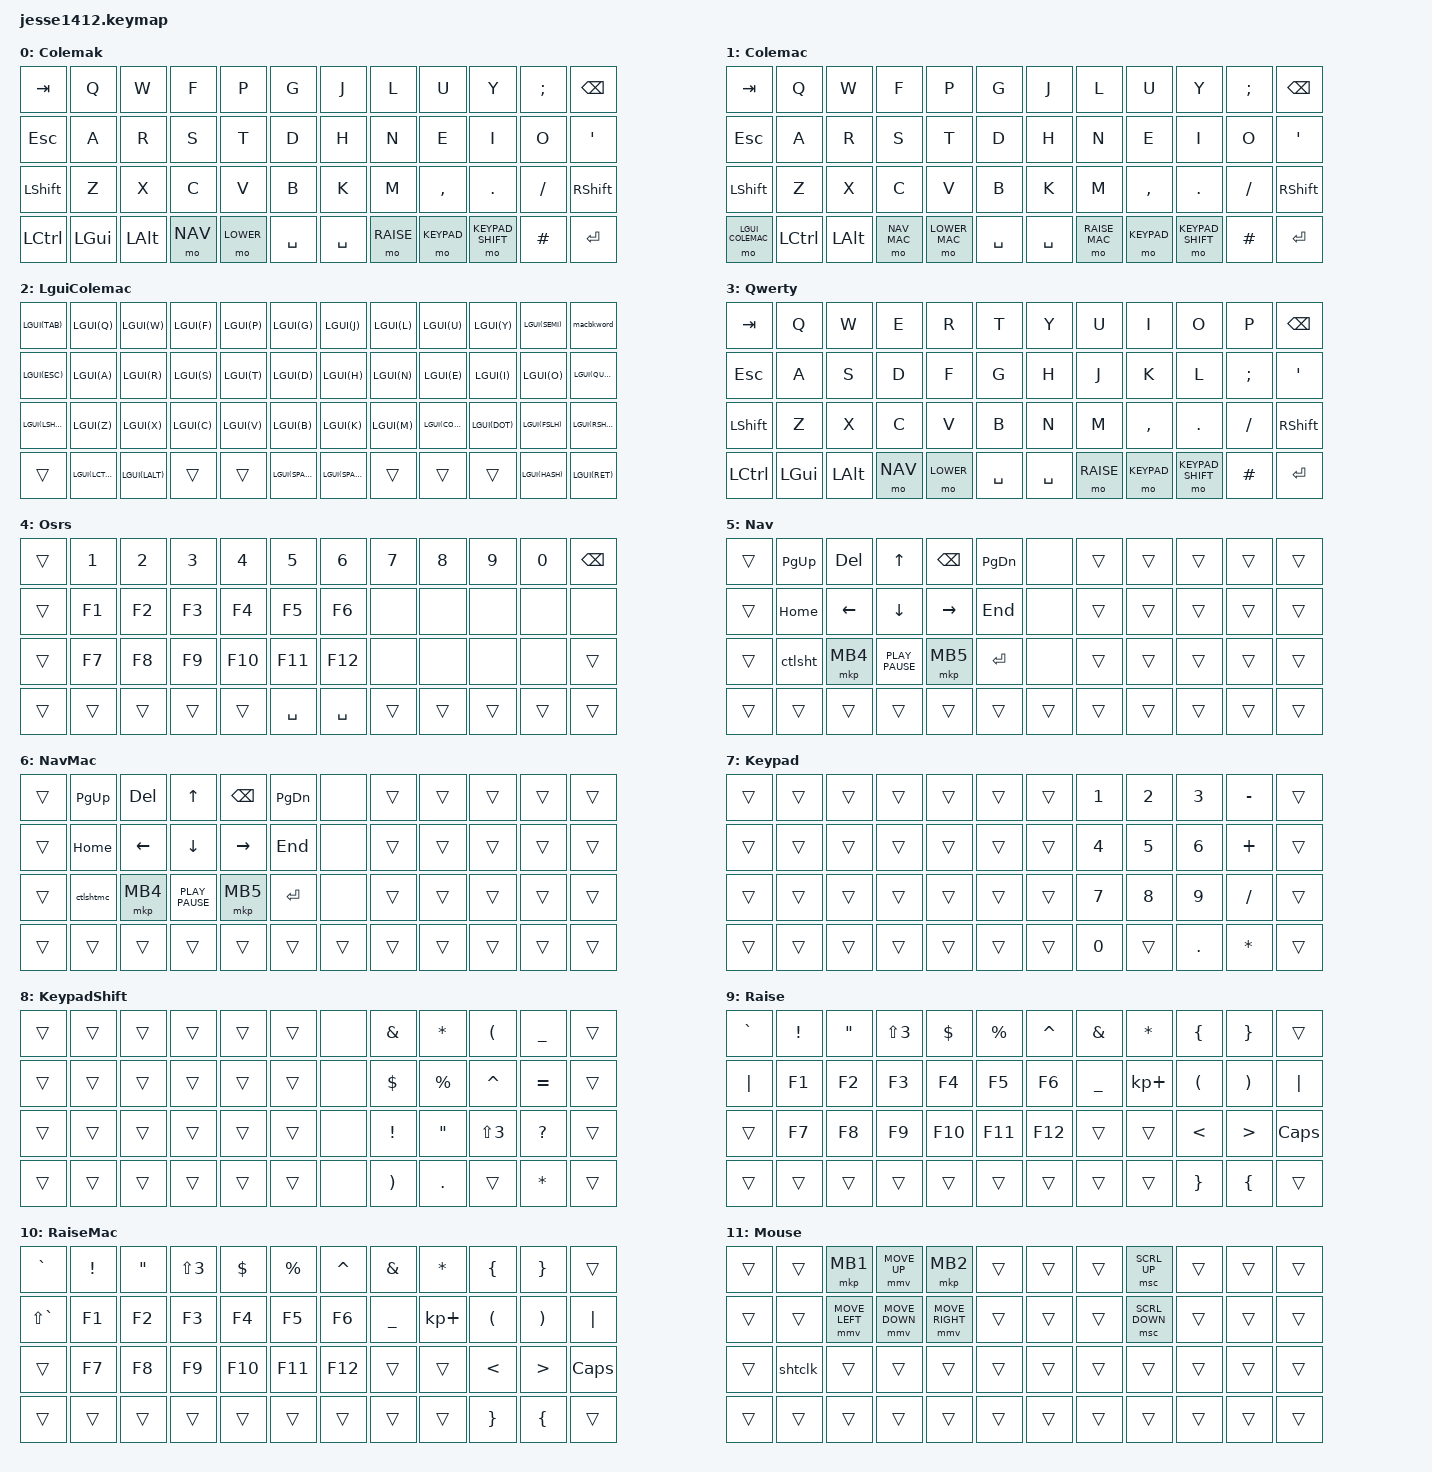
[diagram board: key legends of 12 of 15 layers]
/*
 * Copyright (c) 2022 Pete Johanson
 *
 * SPDX-License-Identifier: MIT
 */

#define ZMK_POINTING_DEFAULT_MOVE_VAL 600  // default: 600
#define ZMK_POINTING_DEFAULT_SCRL_VAL 10    // default: 10

#include <behaviors.dtsi>
#include <dt-bindings/zmk/keys.h>
#include <dt-bindings/zmk/bt.h>
#include <dt-bindings/zmk/outputs.h>
#include <dt-bindings/zmk/pointing.h>


// Layers
#define COLEMAK 0
#define COLEMAC 1
#define LGUI_COLEMAC 2
#define QWERTY 3
#define OSRS 4
#define NAV 5
#define NAV_MAC 6
#define KEYPAD 7
#define KEYPAD_SHIFT 8
#define RAISE 9
#define RAISE_MAC 10
#define MOUSE 11
#define LOWER 12
#define LOWER_MAC 13
#define ADJUST 14

// Using layer taps on thumbs, having quick tap as well helps w/ repeating space/backspace
&lt { quick_tap_ms = <200>; };

/ {
    chosen {
       zmk,physical-layout = &layout_ortho_4x12_all1u;
    };

    macros {
        ctlsht: ctlsht {
            compatible = "zmk,behavior-macro";
            #binding-cells = <0>;
            bindings
                = <&macro_press &kp LSHFT>
                , <&macro_press &kp LCTRL>
                , <&macro_pause_for_release>
                , <&macro_release &kp LCTRL>
                , <&macro_release &kp LSHFT>
                ;
        };
        ctlshtmc: ctlshtmc {
            compatible = "zmk,behavior-macro";
            #binding-cells = <0>;
            bindings
                = <&macro_press &kp LSHFT>
                , <&macro_press &kp LALT>
                , <&macro_pause_for_release>
                , <&macro_release &kp LALT>
                , <&macro_release &kp LSHFT>
                ;
        };
        // macpip: macpip {
        //     compatible = "zmk,behavior-macro";
        //     #binding-cells = <0>;
        //     bindings
        //         = <&macro_press &kp LSHFT>
        //         , <&macro_press  &kp GRAVE>
        //         , <&macro_pause_for_release>
        //         , <&macro_release &kp LSHFT>
        //         , <&macro_release &kp GRAVE>
        //         ;
        // };
        macbkword: macbkword {
            compatible = "zmk,behavior-macro";
            #binding-cells = <0>;
            bindings
                = <&macro_press &kp LALT>
                , <&macro_press &kp BSPC>
                , <&macro_pause_for_release>
                , <&macro_release &kp BSPC>
                , <&macro_release &kp LALT>
                ;
        };
        shtclk: shtclk {
            compatible = "zmk,behavior-macro";
            #binding-cells = <0>;
            bindings
                = <&macro_press &kp LSHFT>
                , <&macro_press &mkp LCLK>
                , <&macro_pause_for_release>
                , <&macro_release &mkp LCLK>
                , <&macro_release &kp LSHFT>
                ;
        };
    };
    
    // combos {
    //     compatible = "zmk,combos";
    //     combo_macbksp {
    //         timeout-ms = <50>;
    //         key-positions = <0 1>;
    //         bindings = <&kp ESC>;
    //     };
    // };

    // tap_dances {
    // 	shifty: shift_caps_word {
    //         compatible = "zmk,behavior-tap-dance";
    //         label = "TD_SHIFTY";
    //         #binding-cells = <0>;
    //         tapping-term-ms = <150>;
    //         bindings = <&kp LSHFT>, <&caps_word>;
	//     };
    // };

    conditional_layers {
        compatible = "zmk,conditional-layers";
        low_raise {
            if-layers = <LOWER RAISE>;
            then-layer = <ADJUST>;
        };
        mac_low_raise {
            if-layers = <LOWER_MAC RAISE_MAC>;
            then-layer = <ADJUST>;
        };
        nav_raise {
            if-layers = <NAV RAISE>;
            then-layer = <MOUSE>;
        };
        mac_nav_raise {
            if-layers = <NAV_MAC RAISE_MAC>;
            then-layer = <MOUSE>;
        };
    };

    keymap {
        compatible = "zmk,keymap";

        colemak_layer {
            label = "Colemak";
            bindings = <
 &kp TAB    &kp Q      &kp W      &kp F       &kp P          &kp G          &kp J            &kp L          &kp U       &kp Y            &kp SEMI      &kp BKSP
 &kp ESC    &kp A      &kp R      &kp S       &kp T          &kp D          &kp H            &kp N          &kp E       &kp I            &kp O         &kp QUOT
 &kp LSHFT  &kp Z      &kp X      &kp C       &kp V          &kp B          &kp K            &kp M          &kp COMMA   &kp DOT          &kp FSLH      &kp RSHFT
 &kp LCTRL  &kp LGUI   &kp LALT   &mo NAV     &mo LOWER      &kp SPACE      &kp SPACE        &mo RAISE      &mo KEYPAD  &mo KEYPAD_SHIFT &kp HASH      &kp RET
            >;
        };
        colemac_layer {
            label = "Colemac";
            bindings = <
 &kp TAB            &kp Q      &kp W      &kp F       &kp P          &kp G          &kp J            &kp L          &kp U       &kp Y            &kp SEMI      &kp BKSP
 &kp ESC            &kp A      &kp R      &kp S       &kp T          &kp D          &kp H            &kp N          &kp E       &kp I            &kp O         &kp QUOT
 &kp LSHFT          &kp Z      &kp X      &kp C       &kp V          &kp B          &kp K            &kp M          &kp COMMA   &kp DOT          &kp FSLH      &kp RSHFT
 &mo LGUI_COLEMAC   &kp LCTRL  &kp LALT   &mo NAV_MAC &mo LOWER_MAC  &kp SPACE      &kp SPACE        &mo RAISE_MAC  &mo KEYPAD  &mo KEYPAD_SHIFT &kp HASH      &kp RET
            >;
        };
        lgui_colemac_layer {
            label = "LguiColemac";
            bindings = <
 &kp LGUI(TAB)    &kp LGUI(Q)      &kp LGUI(W)      &kp LGUI(F)       &kp LGUI(P)          &kp LGUI(G)          &kp LGUI(J)            &kp LGUI(L)          &kp LGUI(U)       &kp LGUI(Y)            &kp LGUI(SEMI)      &macbkword
 &kp LGUI(ESC)    &kp LGUI(A)      &kp LGUI(R)      &kp LGUI(S)       &kp LGUI(T)          &kp LGUI(D)          &kp LGUI(H)            &kp LGUI(N)          &kp LGUI(E)       &kp LGUI(I)            &kp LGUI(O)         &kp LGUI(QUOT)
 &kp LGUI(LSHFT)  &kp LGUI(Z)      &kp LGUI(X)      &kp LGUI(C)       &kp LGUI(V)          &kp LGUI(B)          &kp LGUI(K)            &kp LGUI(M)          &kp LGUI(COMMA)   &kp LGUI(DOT)          &kp LGUI(FSLH)      &kp LGUI(RSHFT)
 &trans           &kp LGUI(LCTRL)  &kp LGUI(LALT)   &trans            &trans               &kp LGUI(SPACE)      &kp LGUI(SPACE)        &trans               &trans            &trans                 &kp LGUI(HASH)      &kp LGUI(RET)
            >;
        };
        qwerty_layer {
            label = "Qwerty";
            bindings = <
 &kp TAB    &kp Q      &kp W      &kp E       &kp R          &kp T          &kp Y            &kp U          &kp I       &kp O            &kp P         &kp BKSP
 &kp ESC    &kp A      &kp S      &kp D       &kp F          &kp G          &kp H            &kp J          &kp K       &kp L            &kp SEMI      &kp QUOT
 &kp LSHFT  &kp Z      &kp X      &kp C       &kp V          &kp B          &kp N            &kp M          &kp COMMA   &kp DOT          &kp FSLH      &kp RSHFT
 &kp LCTRL  &kp LGUI   &kp LALT   &mo NAV     &mo LOWER      &kp SPACE      &kp SPACE        &mo RAISE      &mo KEYPAD  &mo KEYPAD_SHIFT &kp HASH      &kp RET
            >;
        };
        osrs_layer {
            label = "Osrs";
            bindings = <
 &trans     &kp N1     &kp N2     &kp N3      &kp N4         &kp N5         &kp N6           &kp N7         &kp N8      &kp N9        &kp N0        &kp BKSP
 &trans     &kp F1     &kp F2     &kp F3      &kp F4         &kp F5         &kp F6           &none          &none       &none         &none         &none 
 &trans     &kp F7     &kp F8     &kp F9      &kp F10        &kp F11        &kp F12          &none          &none       &none         &none         &trans  
 &trans     &trans     &trans     &trans      &trans         &kp SPACE      &kp SPACE        &trans         &trans      &trans        &trans        &trans  
            >;
        };
        nav_layer {
            label = "Nav";
            bindings = <
 &trans     &kp PG_UP  &kp DEL    &kp UP           &kp BKSP       &kp PG_DN      &none            &trans         &trans      &trans        &trans        &trans
 &trans     &kp HOME   &kp LEFT   &kp DOWN         &kp RIGHT      &kp END        &none            &trans         &trans      &trans        &trans        &trans
 &trans     &ctlsht    &mkp MB4   &kp K_PLAY_PAUSE &mkp MB5       &kp RET        &none            &trans         &trans      &trans        &trans        &trans
 &trans     &trans     &trans     &trans           &trans         &trans         &trans           &trans         &trans      &trans        &trans        &trans
            >;
        };
        nav_mac_layer {
            label = "NavMac";
            bindings = <
 &trans     &kp PG_UP  &kp DEL    &kp UP           &kp BKSP       &kp PG_DN      &none            &trans         &trans      &trans        &trans        &trans
 &trans     &kp HOME   &kp LEFT   &kp DOWN         &kp RIGHT      &kp END        &none            &trans         &trans      &trans        &trans        &trans
 &trans     &ctlshtmc  &mkp MB4   &kp K_PLAY_PAUSE &mkp MB5       &kp RET        &none            &trans         &trans      &trans        &trans        &trans
 &trans     &trans     &trans     &trans           &trans         &trans         &trans           &trans         &trans      &trans        &trans        &trans
            >;
        };
        keypad_layer {
            label = "Keypad";
            bindings = <
 &trans     &trans     &trans     &trans      &trans         &trans         &trans           &kp N1         &kp N2      &kp N3        &kp MINUS       &trans
 &trans     &trans     &trans     &trans      &trans         &trans         &trans           &kp N4         &kp N5      &kp N6        &kp PLUS        &trans
 &trans     &trans     &trans     &trans      &trans         &trans         &trans           &kp N7         &kp N8      &kp N9        &kp FSLH        &trans
 &trans     &trans     &trans     &trans      &trans         &trans         &trans           &kp N0         &trans      &kp DOT       &kp STAR        &trans
            >;
        };
        keypad_shift_layer {
            label = "KeypadShift";
            bindings = <
 &trans     &trans     &trans     &trans      &trans         &trans         &none           &kp AMPS       &kp STAR    &kp LPAR      &kp UNDER       &trans
 &trans     &trans     &trans     &trans      &trans         &trans         &none           &kp DLLR       &kp PRCNT   &kp CARET     &kp EQUAL       &trans
 &trans     &trans     &trans     &trans      &trans         &trans         &none           &kp EXCL       &kp DQT     &kp LS(N3)    &kp QMARK       &trans
 &trans     &trans     &trans     &trans      &trans         &trans         &none           &kp RPAR       &kp DOT     &trans        &kp STAR        &trans
            >;
        };
        raise_layer {
            label = "Raise";
            bindings = <
 &kp GRAVE  &kp EXCL   &kp DQT    &kp LS(N3)  &kp DLLR       &kp PRCNT      &kp CARET       &kp AMPS       &kp STAR    &kp LBRC      &kp RBRC        &trans
 &kp PIPE   &kp F1     &kp F2     &kp F3      &kp F4         &kp F5         &kp F6          &kp UNDER      &kp KP_PLUS &kp LPAR      &kp RPAR        &kp PIPE
 &trans     &kp F7     &kp F8     &kp F9      &kp F10        &kp F11        &kp F12         &trans         &trans      &kp LT        &kp GT          &kp CAPS
 &trans     &trans     &trans     &trans      &trans         &trans         &trans          &trans         &trans      &kp RBRC      &kp LBRC        &trans
            >;
        };
        raise_mac_layer {
            label = "RaiseMac";
            bindings = <
 &kp GRAVE     &kp EXCL   &kp DQT    &kp LS(N3)  &kp DLLR       &kp PRCNT      &kp CARET       &kp AMPS       &kp STAR    &kp LBRC      &kp RBRC        &trans
 &kp LS(GRAVE) &kp F1     &kp F2     &kp F3      &kp F4         &kp F5         &kp F6          &kp UNDER      &kp KP_PLUS &kp LPAR      &kp RPAR        &kp PIPE
 &trans        &kp F7     &kp F8     &kp F9      &kp F10        &kp F11        &kp F12         &trans         &trans      &kp LT        &kp GT          &kp CAPS
 &trans        &trans     &trans     &trans      &trans         &trans         &trans          &trans         &trans      &kp RBRC      &kp LBRC        &trans
            >;
        };
        mouse_layer {
            label = "Mouse";
            bindings = <
 &trans     &trans     &mkp MB1       &mmv MOVE_UP    &mkp MB2         &trans         &trans           &trans         &msc SCRL_UP   &trans        &trans        &trans
 &trans     &trans     &mmv MOVE_LEFT &mmv MOVE_DOWN  &mmv MOVE_RIGHT  &trans         &trans           &trans         &msc SCRL_DOWN &trans        &trans        &trans    
 &trans     &shtclk    &trans         &trans          &trans           &trans         &trans           &trans         &trans         &trans        &trans        &trans    
 &trans     &trans     &trans         &trans          &trans           &trans         &trans           &trans         &trans         &trans        &trans        &trans    
            >;
        };
        lower_layer {
            label = "Lower";
            bindings = <
 &kp GRAVE  &kp N1     &kp N2     &kp N3      &kp N4         &kp N5         &kp N6          &kp N7         &kp N8      &kp N9        &kp N0          &trans
 &kp BSLH   &kp F1     &kp F2     &kp F3      &kp F4         &kp F5         &kp F6          &kp MINUS      &kp EQUAL   &trans        &trans          &trans
 &trans     &kp F7     &kp F8     &kp F9      &kp F10        &kp F11        &kp F12         &trans         &trans      &trans        &trans          &kp CAPS
 &trans     &trans     &trans     &trans      &trans         &trans         &trans          &trans         &trans      &trans        &trans          &trans
            >;
        };
        lower_mac_layer {
            label = "LowerMac";
            bindings = <
 &kp GRAVE  &kp N1     &kp N2     &kp N3      &kp N4         &kp N5         &kp N6          &kp N7         &kp N8      &kp N9        &kp N0          &trans
 &kp BSLH   &kp F1     &kp F2     &kp F3      &kp F4         &kp F5         &kp F6          &kp MINUS      &kp EQUAL   &trans        &trans          &trans
 &trans     &kp F7     &kp F8     &kp F9      &kp F10        &kp F11        &kp F12         &trans         &trans      &trans        &trans          &kp CAPS
 &trans     &trans     &trans     &trans      &trans         &trans         &trans          &trans         &trans      &trans        &trans          &trans
            >;
        };
        adjust_layer {
            label = "Adjust";
            bindings = <
 &out OUT_TOG &bt BT_SEL 1 &bt BT_SEL 2 &bt BT_SEL 3 &bt BT_SEL 4  &bt BT_SEL 5   &trans           &trans         &trans      &trans        &trans        &trans
 &bt BT_CLR   &trans       &trans       &trans       &trans        &trans         &trans           &to QWERTY     &to COLEMAK &trans        &trans        &trans    
 &sys_reset   &trans       &trans       &trans       &trans        &trans         &trans           &to OSRS       &to COLEMAC &trans        &trans        &trans    
 &bootloader  &trans       &trans       &trans       &trans        &trans         &trans           &trans         &trans      &trans        &trans        &trans    
            >;
        };
    };
};

